# WBZ351 register map
Vendor: Microchip
Registers are 32-bit, read-write, reset 0x0 unless marked. A register's access mark holds for its fields unless they carry their own. Addresses are absolute, and some are shared; only a register's first bit layout is shown; [hi:lo] are bit positions; {n}, {i} and the like mark numbered series.

## GPIOA
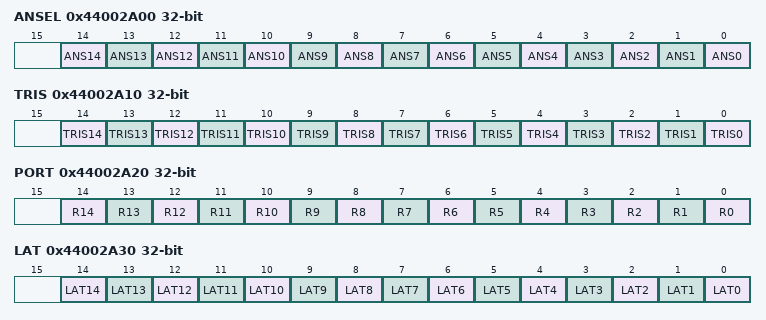
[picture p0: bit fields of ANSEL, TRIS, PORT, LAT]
0x44002A00 ANSEL
  [n] ANS{n} (n=0..14)
0x44002A04 ANSELCLR
0x44002A08 ANSELSET
0x44002A0C ANSELINV
0x44002A10 TRIS
  [n] TRIS{n} (n=0..14)
0x44002A14 TRISCLR
0x44002A18 TRISSET
0x44002A1C TRISINV
0x44002A20 PORT
  [n] R{n} (n=0..14)
0x44002A24 PORTCLR
0x44002A28 PORTSET
0x44002A2C PORTINV
0x44002A30 LAT
  [n] LAT{n} (n=0..14)
0x44002A34 LATCLR
0x44002A38 LATSET
0x44002A3C LATINV
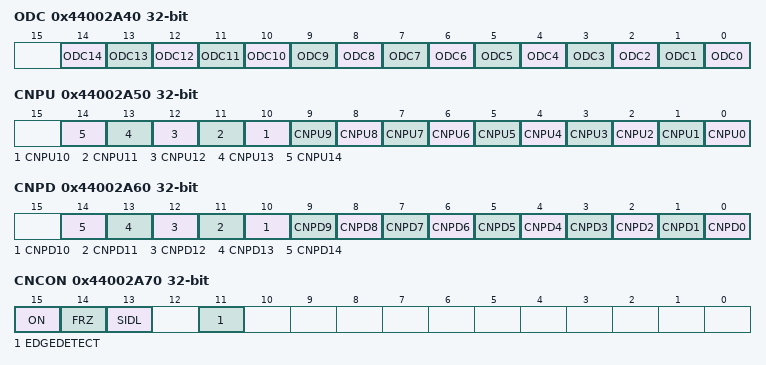
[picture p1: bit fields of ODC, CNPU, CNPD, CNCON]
0x44002A40 ODC
  [n] ODC{n} (n=0..14)
0x44002A44 ODCCLR
0x44002A48 ODCSET
0x44002A4C ODCINV
0x44002A50 CNPU
  [n] CNPU{n} (n=0..14)
0x44002A54 CNPUCLR
0x44002A58 CNPUSET
0x44002A5C CNPUINV
0x44002A60 CNPD
  [n] CNPD{n} (n=0..14)
0x44002A64 CNPDCLR
0x44002A68 CNPDSET
0x44002A6C CNPDINV
0x44002A70 CNCON
  [15] ON, [14] FRZ, [13] SIDL, [11] EDGEDETECT
0x44002A74 CNCONCLR
0x44002A78 CNCONSET
0x44002A7C CNCONINV
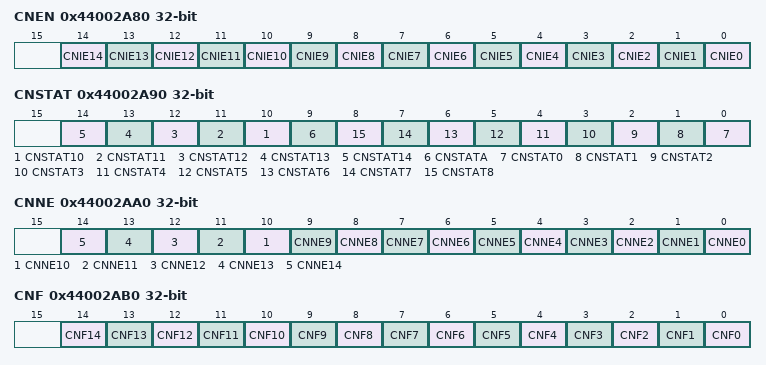
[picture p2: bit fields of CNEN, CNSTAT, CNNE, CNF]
0x44002A80 CNEN
  [n] CNIE{n} (n=0..14)
0x44002A84 CNENCLR
0x44002A88 CNENSET
0x44002A8C CNENINV
0x44002A90 CNSTAT
  [n] CNSTAT{n} (n=10..14), [9] CNSTATA, [n] CNSTAT{n} (n=0..8)
0x44002A94 CNSTATCLR
0x44002A98 CNSTATSET
0x44002A9C CNSTATINV
0x44002AA0 CNNE
  [n] CNNE{n} (n=0..14)
0x44002AA4 CNNECLR
0x44002AA8 CNNESET
0x44002AAC CNNEINV
0x44002AB0 CNF
  [n] CNF{n} (n=0..14)
0x44002AB4 CNFCLR
0x44002AB8 CNFSET
0x44002ABC CNFINV
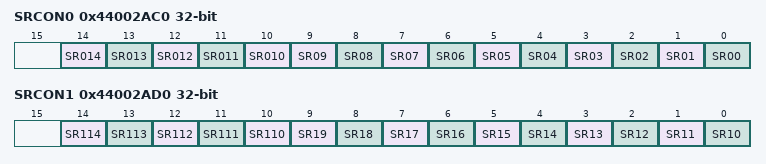
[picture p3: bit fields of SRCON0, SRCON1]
0x44002AC0 SRCON0
  [n] SR{n:03} (n=10..14), [n] SR{n:02} (n=0..9)
0x44002AC4 SRCON0CLR
0x44002AC8 SRCON0SET
0x44002ACC SRCON0INV
0x44002AD0 SRCON1
  [n-100] SR{n} (n=110..114), [n-10] SR{n} (n=10..19)
0x44002AD4 SRCON1CLR
0x44002AD8 SRCON1SET
0x44002ADC SRCON1INV

## GPIOB
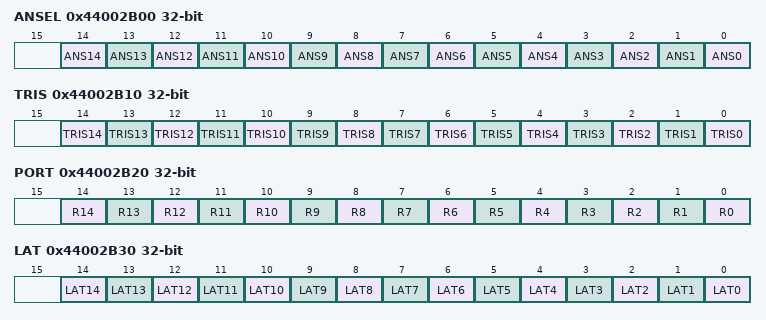
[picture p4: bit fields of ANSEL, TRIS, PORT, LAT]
0x44002B00 ANSEL
  [n] ANS{n} (n=0..14)
0x44002B04 ANSELCLR
0x44002B08 ANSELSET
0x44002B0C ANSELINV
0x44002B10 TRIS
  [n] TRIS{n} (n=0..14)
0x44002B14 TRISCLR
0x44002B18 TRISSET
0x44002B1C TRISINV
0x44002B20 PORT
  [n] R{n} (n=0..14)
0x44002B24 PORTCLR
0x44002B28 PORTSET
0x44002B2C PORTINV
0x44002B30 LAT
  [n] LAT{n} (n=0..14)
0x44002B34 LATCLR
0x44002B38 LATSET
0x44002B3C LATINV
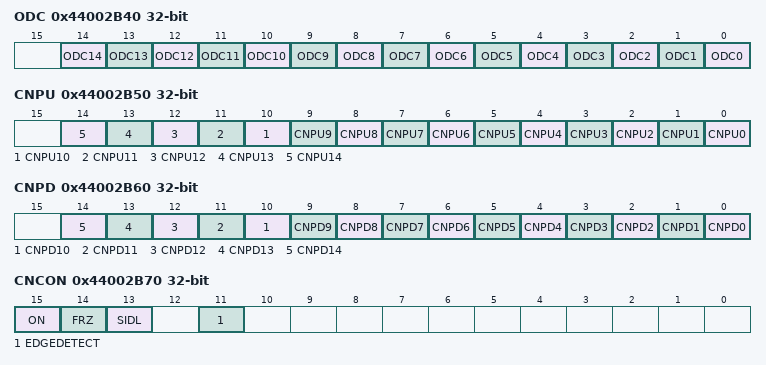
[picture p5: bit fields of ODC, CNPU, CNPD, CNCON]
0x44002B40 ODC
  [n] ODC{n} (n=0..14)
0x44002B44 ODCCLR
0x44002B48 ODCSET
0x44002B4C ODCINV
0x44002B50 CNPU
  [n] CNPU{n} (n=0..14)
0x44002B54 CNPUCLR
0x44002B58 CNPUSET
0x44002B5C CNPUINV
0x44002B60 CNPD
  [n] CNPD{n} (n=0..14)
0x44002B64 CNPDCLR
0x44002B68 CNPDSET
0x44002B6C CNPDINV
0x44002B70 CNCON
  [15] ON, [14] FRZ, [13] SIDL, [11] EDGEDETECT
0x44002B74 CNCONCLR
0x44002B78 CNCONSET
0x44002B7C CNCONINV
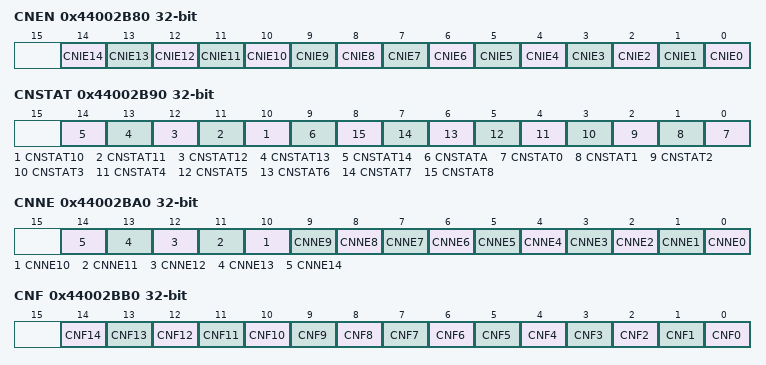
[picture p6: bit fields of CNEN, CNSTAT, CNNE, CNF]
0x44002B80 CNEN
  [n] CNIE{n} (n=0..14)
0x44002B84 CNENCLR
0x44002B88 CNENSET
0x44002B8C CNENINV
0x44002B90 CNSTAT
  [n] CNSTAT{n} (n=10..14), [9] CNSTATA, [n] CNSTAT{n} (n=0..8)
0x44002B94 CNSTATCLR
0x44002B98 CNSTATSET
0x44002B9C CNSTATINV
0x44002BA0 CNNE
  [n] CNNE{n} (n=0..14)
0x44002BA4 CNNECLR
0x44002BA8 CNNESET
0x44002BAC CNNEINV
0x44002BB0 CNF
  [n] CNF{n} (n=0..14)
0x44002BB4 CNFCLR
0x44002BB8 CNFSET
0x44002BBC CNFINV
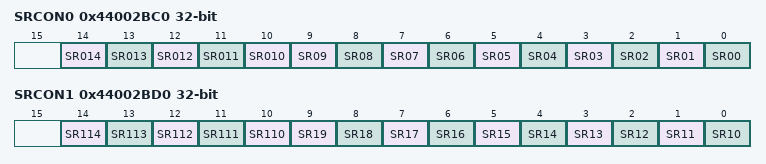
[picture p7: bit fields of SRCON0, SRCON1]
0x44002BC0 SRCON0
  [n] SR{n:03} (n=10..14), [n] SR{n:02} (n=0..9)
0x44002BC4 SRCON0CLR
0x44002BC8 SRCON0SET
0x44002BCC SRCON0INV
0x44002BD0 SRCON1
  [n-100] SR{n} (n=110..114), [n-10] SR{n} (n=10..19)
0x44002BD4 SRCON1CLR
0x44002BD8 SRCON1SET
0x44002BDC SRCON1INV

## ROT
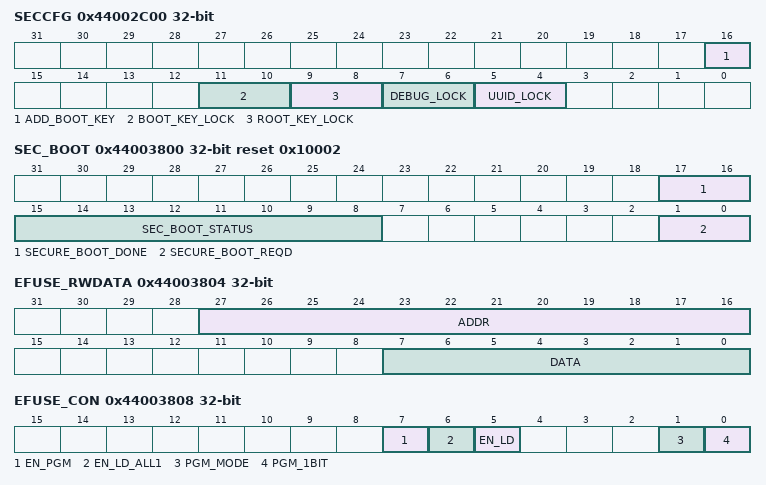
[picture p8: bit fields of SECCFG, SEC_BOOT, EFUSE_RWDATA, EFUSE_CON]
0x44002C00 SECCFG
  [16] ADD_BOOT_KEY — Additional boot Key bit
  [11:10] BOOT_KEY_LOCK — Lock bits for Secure Boot/OTA Key
    0=BOOT_KEY_NOT_LCK_0 (Secure boot key is not locked); 1=BOOT_KEY_LCK_1 (Secure boot key is locked and cannot be programmed); 2=BOOT_KEY_LCK_2 (Secure boot key is locked and cannot be programmed); 3=BOOT_KEY_LCK_3 (Secure boot key is locked and cannot be programmed)
  [9:8] ROOT_KEY_LOCK — Lock bits for storage root Key
    0=ROOT_KEY_NOT_LCK_0 (Storage root key is not locked); 1=ROOT_KEY_LCK_1 (Storage root key is locked and cannot be programmed); 2=ROOT_KEY_LCK_2 (Storage root key is locked and cannot be programmed); 3=ROOT_KEY_LCK_3 (Storage root key is locked and cannot be programmed)
  [7:6] DEBUG_LOCK — Lock bits for debug/programming
    0=DEBUG_NOT_LCK_0 (Debug is not locked); 1=DEBUG_LCK_1 (Debug is locked); 2=DEBUG_LCK_2 (Debug is locked); 3=DEBUG_LCK_3 (Debug is locked)
  [5:4] UUID_LOCK — Programming lock bits for Unique ID fuses
    0=UUID_NOT_LCK_0 (Unique ID is not locked); 1=UUID_LCK_1 (Unique ID is locked and cannot be programmed); 2=UUID_LCK_2 (Unique ID is locked and cannot be programmed); 3=UUID_LCK_3 (Unique ID is locked and cannot be programmed)
0x44003800 SEC_BOOT reset 0x10002
  [17:16] SECURE_BOOT_DONE — Bits to indicate that secure boot is done
    0=SEC_BOOT_DONE_0 (S ecure boot is done); 1=SEC_BOOT_NOT_DONE_1 (S ecure boot is not done); 2=SEC_BOOT_NOT_DONE_2 (S ecure boot is not done); 3=SEC_BOOT_DONE_3 (S ecure boot is done)
  [15:8] SEC_BOOT_STATUS — Bits to indicate that secure boot status
  [1:0] SECURE_BOOT_REQD — Bits to indicate that secure boot is required on the next device reset.
    0=SEC_BOOT_REQD_0 (Secure boot code authentication is required); 1=SEC_BOOT_NOT_REQD_1 (Secure boot code authentication is NOT required); 2=SEC_BOOT_NOT_REQD_2 (Secure boot code authentication is NOT required); 3=SEC_BOOT_REQD_3 (Secure boot code authentication is required)
0x44003804 EFUSE_RWDATA
  [27:16] ADDR — eFuse Program/Read Address
  [7:0] DATA — eFuse Program (Write) Data
0x44003808 EFUSE_CON
  [7] EN_PGM — eFuse Programming Start bit
    0=EN_PGM_COMPLETED (EFuse Programming operation has completed); 1=EN_PGM_START (Start eFuse Programming operation)
  [6] EN_LD_ALL1 — eFuse Panel Read Start bit for loading into the holding registers
    0=ENLD_ALL1_READ_COMPLETED (EFuse Read operation has completed); 1=ENLD_ALL1_READ_START (Start eFuse Read operation for entire eFuse panel)
  [5] EN_LD — eFuse Word Read Start bit for loading the fuse byte pointed by ADDR field into the holding register
    0=ENLD_READ_COMPLETED (EFuse Read operation has completed); 1=ENLD_READ_START (Start eFuse Read operation for specified eFuse word as addressed in EFUSE_RWDATA register)
  [1] PGM_MODE — eFuse Programming Mode Enable bit
    0=PGM_MODE_DISABLED (EFuse Programming disabled); 1=PGM_MODE_ENABLED (EFuse Programming enabled)
  [0] PGM_1BIT — eFuse CTRL to program 1 bit at a time. Valid only when EN_PGM is set
    0=EFUSE_RW_15_0 (EFuse controller will program EFUSE_RWDATA.DATA[15:0] to the address in EFUSE_RWDATA.ADDR[11:3]); 1=EFUSE_RW_0 (EFuse controller will program EFUSE_RWDATA.DATA[0] to the address in EFUSE_RWDATA.ADDR[11:0])
